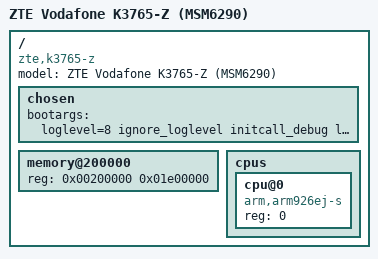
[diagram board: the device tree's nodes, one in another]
/dts-v1/;

/*
 * Preserve the initialized ARMPRG runtime and its working memory.
 * The first kernel probe only borrows it for pre-MMU trace output.
 */
/memreserve/ 0x00800000 0x00100000;

/* Keep the uploaded DTB stable during early bring-up. */
/memreserve/ 0x01f80000 0x00010000;

/ {
	compatible = "zte,k3765-z", "qcom,msm6290";
	model = "ZTE Vodafone K3765-Z (MSM6290)";

	#address-cells = <1>;
	#size-cells = <1>;

	chosen {
		/*
		 * Temporary bring-up value: the hardware timer is not registered yet,
		 * so automatic delay calibration cannot observe advancing jiffies.
		 */
		bootargs = "loglevel=8 ignore_loglevel initcall_debug lpj=1000000";
	};

	/*
	 * Linux v6.1's ARM DT-assisted AUTO_ZRELADDR path requires the selected
	 * physical base to be 2 MiB aligned.  Leave the first MiB of the observed
	 * SDRAM window unused for this first probe.
	 */
	memory@200000 {
		device_type = "memory";
		reg = <0x00200000 0x01e00000>;
	};

	cpus {
		#address-cells = <1>;
		#size-cells = <0>;

		cpu@0 {
			device_type = "cpu";
			compatible = "arm,arm926ej-s";
			reg = <0>;
		};
	};
};
